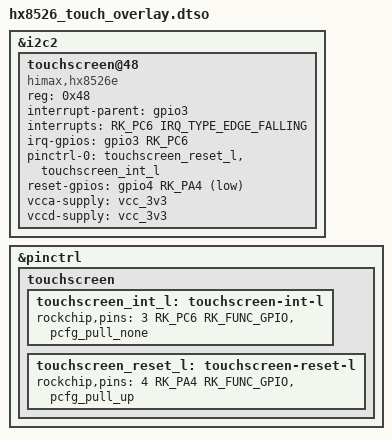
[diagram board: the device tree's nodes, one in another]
/dts-v1/;
/plugin/;			/* Identifies this as an overlay */

#include <dt-bindings/gpio/gpio.h>
#include <dt-bindings/input/input.h>
#include <dt-bindings/interrupt-controller/irq.h>
#include <dt-bindings/clock/rk3568-cru.h>
#include <dt-bindings/pinctrl/rockchip.h>
#include <dt-bindings/soc/rockchip,vop2.h>

&i2c2 {				/* We are modifying the i2c2 node of the base tree, an alias for i2c@fe5b0000 */
	/* The next two are already set in the base tree we're overlaying onto,
	 * but dtc doesn't know this, so it emits warnings. Either way, they
	 * describe what the meaning of all the children's reg properties is. In
	 * this case, that the only cell in reg describes what address the device
	 * listens on.
	 */
	#address-cells = <1>;
	#size-cells = <0>;
	status = "okay";	/* Enable the I2C node of rk356x.dtsi */

	touchscreen@48 { /* Touchscreen at 0x48 */
        compatible = "himax,hx8526e", "himax,hx852es";
        reg = <0x48>;
        interrupt-parent = <&gpio3>;
        interrupts = <RK_PC6 IRQ_TYPE_EDGE_FALLING>;
		irq-gpios = <&gpio3 RK_PC6 GPIO_ACTIVE_HIGH>;
		pinctrl-names = "default";
		pinctrl-0 = <&touchscreen_reset_l &touchscreen_int_l>;
        reset-gpios = <&gpio4 RK_PA4 GPIO_ACTIVE_LOW>;
        vcca-supply = <&vcc_3v3>;
        vccd-supply = <&vcc_3v3>;
	};
};

&pinctrl {
	touchscreen {
		touchscreen_int_l: touchscreen-int-l { /* gpio bank 3 (gpio3), pin C6 */
			rockchip,pins = <3 RK_PC6 RK_FUNC_GPIO &pcfg_pull_none>;
		};

		/* Set a pull-up bias on the reset pin as it's active low */
		touchscreen_reset_l: touchscreen-reset-l {
			rockchip,pins = <4 RK_PA4 RK_FUNC_GPIO &pcfg_pull_up>;
		};
	};
};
